# RZ/A1H register map
Vendor: Renesas
Registers are 32-bit, read-write, reset 0x0 unless marked. A register's access mark holds for its fields unless they carry their own. Offsets are from the block's base; [hi:lo] are bit positions; {n}, {i} and the like mark numbered series.

## RSPI0
Base 0xE800C800
Same registers: RSPI1 0xE800D000, RSPI2 0xE800D800, RSPI3 0xE800E000, RSPI4 0xE800E800
0x00 SPCR 8-bit
0x01 SSLP 8-bit
0x02 SPPCR 8-bit
0x03 SPSR 8-bit
0x04 SPDR
0x08 SPSCR 8-bit
0x09 SPSSR 8-bit
0x0A SPBR 8-bit
0x0B SPDCR 8-bit
0x0C SPCKD 8-bit
0x0D SSLND 8-bit
0x0E SPND 8-bit
{0x10+2i} SPCMD{i} 16-bit (i=0..3)
0x20 SPBFCR 8-bit
0x22 SPBFDR 16-bit

## RTC
Base 0xFCFF1000
0x00 R64CNT 8-bit
0x02 RSECCNT 8-bit
0x04 RMINCNT 8-bit
0x06 RHRCNT 8-bit
0x08 RWKCNT 8-bit
0x0A RDAYCNT 8-bit
0x0C RMONCNT 8-bit
0x0E RYRCNT 16-bit
0x10 RSECAR 8-bit
0x12 RMINAR 8-bit
0x14 RHRAR 8-bit
0x16 RWKAR 8-bit
0x18 RDAYAR 8-bit
0x1A RMONAR 8-bit
0x1C RCR1 8-bit
0x1E RCR2 8-bit
0x20 RYRAR 16-bit
0x24 RCR3 8-bit
0x26 RCR5 8-bit
0x2A RFRH 16-bit
0x2C RFRL 16-bit

## SCIF0
Base 0xE8007000
Same registers: SCIF1 0xE8007800, SCIF2 0xE8008000, SCIF3 0xE8008800, SCIF4 0xE8009000, SCIF5 0xE8009800, SCIF6 0xE800A000, SCIF7 0xE800A800
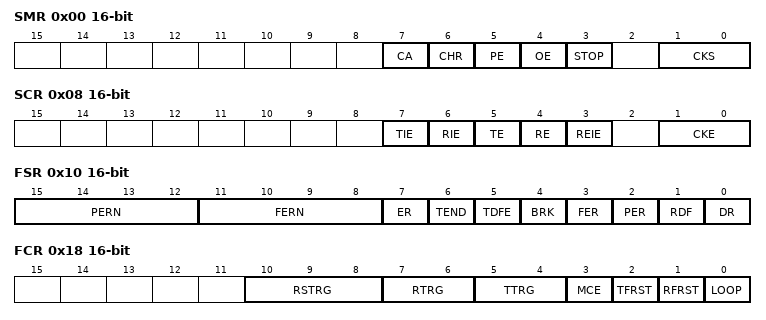
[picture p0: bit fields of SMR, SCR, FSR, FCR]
0x00 SMR 16-bit — SCSMR
  [7] CA
  [6] CHR
  [5] PE
  [4] OE
  [3] STOP
  [1:0] CKS
    0=DIVIDE_BY_1 (P1ϕ); 1=DIVIDE_BY_4 (P1ϕ/4); 2=DIVIDE_BY_16 (P1ϕ/16); 3=DIVIDE_BY_64 (P1ϕ/64)
0x04 BRR 8-bit — SCBRR
  [7:0] D
0x08 SCR 16-bit — SCSCR
  [7] TIE
  [6] RIE
  [5] TE
  [4] RE
  [3] REIE
  [1:0] CKE
    0=INTERNAL_SCK_IN (Asynchronous mode: Internal clock, SCK pin used for input (input signal is ignored). Clock synchronous mode: Internal clock, SCK pin used for synchronous clock output); 1=INTERNAL_SCK_OUT (Internal clock, SCK pin used for synchronous clock output); 2=EXTERNAL_SCK_IN (External clock, SCK pin used for synchronous clock input)
0x0C FTDR 8-bit — SCFTDR
  [7:0] D
0x10 FSR 16-bit — SCFSR
  [15:12] PERN, [11:8] FERN, [7] ER, [6] TEND, [5] TDFE, [4] BRK, [3] FER, [2] PER, [1] RDF, [0] DR
0x14 FRDR 8-bit — SCFRDR
  [7:0] D
0x18 FCR 16-bit — SCFCR
  [10:8] RSTRG
    0=GE_15_BYTES (15 bytes); 1=GE_1_BYTE (1 byte); 2=GE_4_BYTES (4 bytes); 3=GE_6_BYTES (6 bytes); 4=GE_8_BYTES (8 bytes); 5=GE_10_BYTES (10 bytes); 6=GE_12_BYTES (12 bytes); 7=GE_14_BYTES (14 bytes)
  [7:6] RTRG
  [5:4] TTRG
    0=LE_8_BYTES (8 bytes); 1=LE_4_BYTES (4 bytes); 2=LE_2_BYTES (2 bytes); 3=EQ_0_BYTES (0 bytes)
  [3] MCE
  [2] TFRST
  [1] RFRST
  [0] LOOP
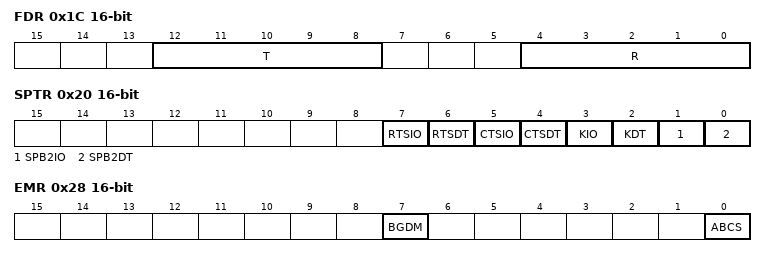
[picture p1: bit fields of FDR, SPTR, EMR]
0x1C FDR 16-bit — SCFDR
  [12:8] T, [4:0] R
0x20 SPTR 16-bit — SCSPTR
  [7] RTSIO, [6] RTSDT, [5] CTSIO, [4] CTSDT, [3] KIO, [2] KDT, [1] SPB2IO, [0] SPB2DT
0x24 LSR 16-bit — SCLSR
  [0] ORER
0x28 EMR 16-bit — SCEMR
  [7] BGDM, [0] ABCS

## SCIM0
Base 0xE800B000
Same registers: SCIM1 0xE800B800
0x00 SMR 8-bit
0x01 BRR 8-bit
0x02 SCR 8-bit
0x03 TDR 8-bit
0x04 SSR 8-bit
0x05 RDR 8-bit
0x06 SCMR 8-bit
0x07 SEMR 8-bit
0x08 SNFR 8-bit
0x0D SECR 8-bit

## SCUX
Base 0xE8208000
{0x0+0x100*i} IPCIR_IPC0_{i} (i=0..3)
{0x4+0x100*i} IPSLR_IPC0_{i} (i=0..3)
{0x400+0x100*i} OPCIR_OPC0_{i} (i=0..3)
{0x404+0x100*i} OPSLR_OPC0_{i} (i=0..3)
{0x800+0x100*i} FFDIR_FFD0_{i} (i=0..3)
{0x804+0x100*i} FDAIR_FFD0_{i} (i=0..3)
{0x808+0x100*i} DRQSR_FFD0_{i} (i=0..3)
{0x80C+0x100*i} FFDPR_FFD0_{i} (i=0..3)
{0x810+0x100*i} FFDBR_FFD0_{i} (i=0..3)
{0x814+0x100*i} DEVMR_FFD0_{i} (i=0..3)
{0x81C+0x100*i} DEVCR_FFD0_{i} (i=0..3)
{0xC00+0x100*i} FFUIR_FFU0_{i} (i=0..3)
{0xC04+0x100*i} FUAIR_FFU0_{i} (i=0..3)
{0xC08+0x100*i} URQSR_FFU0_{i} (i=0..3)
{0xC0C+0x100*i} FFUPR_FFU0_{i} (i=0..3)
{0xC10+0x100*i} UEVMR_FFU0_{i} (i=0..3)
{0xC18+0x100*i} UEVCR_FFU0_{i} (i=0..3)
0x1000 SRCIR0_2SRC0_0
0x1004 SADIR0_2SRC0_0
0x1008 SRCBR0_2SRC0_0
0x100C IFSCR0_2SRC0_0
0x1010 IFSVR0_2SRC0_0
0x1014 SRCCR0_2SRC0_0
0x1018 MNFSR0_2SRC0_0
0x101C BFSSR0_2SRC0_0
0x1020 SC2SR0_2SRC0_0
0x1024 WATSR0_2SRC0_0
0x1028 SEVMR0_2SRC0_0
0x1030 SEVCR0_2SRC0_0
0x1034 SRCIR1_2SRC0_0
0x1038 SADIR1_2SRC0_0
0x103C SRCBR1_2SRC0_0
0x1040 IFSCR1_2SRC0_0
0x1044 IFSVR1_2SRC0_0
0x1048 SRCCR1_2SRC0_0
0x104C MNFSR1_2SRC0_0
0x1050 BFSSR1_2SRC0_0
0x1054 SC2SR1_2SRC0_0
0x1058 WATSR1_2SRC0_0
0x105C SEVMR1_2SRC0_0
0x1064 SEVCR1_2SRC0_0
0x1068 SRCIRR_2SRC0_0
0x1100 SRCIR0_2SRC0_1
0x1104 SADIR0_2SRC0_1
0x1108 SRCBR0_2SRC0_1
0x110C IFSCR0_2SRC0_1
0x1110 IFSVR0_2SRC0_1
0x1114 SRCCR0_2SRC0_1
0x1118 MNFSR0_2SRC0_1
0x111C BFSSR0_2SRC0_1
0x1120 SC2SR0_2SRC0_1
0x1124 WATSR0_2SRC0_1
0x1128 SEVMR0_2SRC0_1
0x1130 SEVCR0_2SRC0_1
0x1134 SRCIR1_2SRC0_1
0x1138 SADIR1_2SRC0_1
0x113C SRCBR1_2SRC0_1
0x1140 IFSCR1_2SRC0_1
0x1144 IFSVR1_2SRC0_1
0x1148 SRCCR1_2SRC0_1
0x114C MNFSR1_2SRC0_1
0x1150 BFSSR1_2SRC0_1
0x1154 SC2SR1_2SRC0_1
0x1158 WATSR1_2SRC0_1
0x115C SEVMR1_2SRC0_1
0x1164 SEVCR1_2SRC0_1
0x1168 SRCIRR_2SRC0_1
{0x1200+0x100*i} DVUIR_DVU0_{i} (i=0..3)
{0x1204+0x100*i} VADIR_DVU0_{i} (i=0..3)
{0x1208+0x100*i} DVUBR_DVU0_{i} (i=0..3)
{0x120C+0x100*i} DVUCR_DVU0_{i} (i=0..3)
{0x1210+0x100*i} ZCMCR_DVU0_{i} (i=0..3)
{0x1214+0x100*i} VRCTR_DVU0_{i} (i=0..3)
{0x1218+0x100*i} VRPDR_DVU0_{i} (i=0..3)
{0x121C+0x100*i} VRDBR_DVU0_{i} (i=0..3)
{0x1220+0x100*i} VRWTR_DVU0_{i} (i=0..3)
{0x1224+4i} VOL{i}R_DVU0_0 (i=0..7)
{0x1244+0x100*i} DVUER_DVU0_{i} (i=0..3)
{0x1248+0x100*i} DVUSR_DVU0_{i} (i=0..3)
{0x124C+0x100*i} VEVMR_DVU0_{i} (i=0..3)
{0x1254+0x100*i} VEVCR_DVU0_{i} (i=0..3)
{0x1324+4i} VOL{i}R_DVU0_1 (i=0..7)
{0x1424+4i} VOL{i}R_DVU0_2 (i=0..7)
{0x1524+4i} VOL{i}R_DVU0_3 (i=0..7)
0x1600 MIXIR_MIX0_0
0x1604 MADIR_MIX0_0
0x1608 MIXBR_MIX0_0
0x160C MIXMR_MIX0_0
0x1610 MVPDR_MIX0_0
0x1614 MDBAR_MIX0_0
0x1618 MDBBR_MIX0_0
0x161C MDBCR_MIX0_0
0x1620 MDBDR_MIX0_0
0x1624 MDBER_MIX0_0
0x1628 MIXSR_MIX0_0
0x1700 SWRSR_CIM
0x1704 DMACR_CIM
{0x1708+4i} DMATD{i}_CIM (i=0..3)
{0x1718+4i} DMATU{i}_CIM (i=0..3)
0x1738 SSIRSEL_CIM
{0x173C+4i} FDTSEL{i}_CIM (i=0..3)
{0x174C+4i} FUTSEL{i}_CIM (i=0..3)
0x175C SSIPMD_CIM
0x1760 SSICTRL_CIM
{0x1764+4i} SRCRSEL{i}_CIM (i=0..3)
0x1774 MIXRSEL_CIM

## SDG0
Base 0xFCFF4800
Same registers: SDG1 0xFCFF4A00, SDG2 0xFCFF4C00, SDG3 0xFCFF4E00
0x00 SGCR1 8-bit
0x01 SGCSR 8-bit
0x02 SGCR2 8-bit
0x03 SGLR 8-bit
0x04 SGTFR 8-bit
0x05 SGSFR 8-bit

## SPDIF
Base 0xE8012000
0x00 TLCA
0x04 TRCA
0x08 TLCS
0x0C TRCS
0x10 TUI
0x14 RLCA
0x18 RRCA
0x1C RLCS
0x20 RRCS
0x24 RUI
0x28 CTRL
0x2C STAT
0x30 TDAD
0x34 RDAD

## SPIBSC0
Base 0x3FEFA000
Same registers: SPIBSC1 0x3FEFB000
0x00 CMNCR
0x04 SSLDR
0x08 SPBCR
0x0C DRCR
0x10 DRCMR
0x14 DREAR
0x18 DROPR
0x1C DRENR
0x20 SMCR
0x24 SMCMR
0x28 SMADR
0x2C SMOPR
0x30 SMENR
0x38 SMRDR0
0x3C SMRDR1
0x40 SMWDR0
0x44 SMWDR1
0x48 CMNSR
0x50 CKDLY
0x58 DRDMCR
0x5C DRDRENR
0x60 SMDMCR
0x64 SMDRENR
0x68 SPODLY

## SSIF0
Base 0xE820B000
Same registers: SSIF1 0xE820B800, SSIF2 0xE820C000, SSIF3 0xE820C800, SSIF4 0xE820D000, SSIF5 0xE820D800
0x00 SSICR
0x04 SSISR
0x10 SSIFCR
0x14 SSIFSR
0x18 SSIFTDR
0x1C SSIFRDR
0x20 SSITDMR
0x24 SSIFCCR
0x28 SSIFCMR
0x2C SSIFCSR

## USB200
Base 0xE8010000
Same registers: USB201 0xE8207000
0x00 SYSCFG0 16-bit
0x02 BUSWAIT 16-bit
0x04 SYSSTS0 16-bit
0x08 DVSTCTR0 16-bit
0x0C TESTMODE 16-bit
0x10 D0FBCFG 16-bit
0x12 D1FBCFG 16-bit
0x14 CFIFO
0x18 D0FIFO
0x1C D1FIFO
0x20 CFIFOSEL 16-bit
0x22 CFIFOCTR 16-bit
0x28 D0FIFOSEL 16-bit
0x2A D0FIFOCTR 16-bit
0x2C D1FIFOSEL 16-bit
0x2E D1FIFOCTR 16-bit
0x30 INTENB0 16-bit
0x32 INTENB1 16-bit
0x36 BRDYENB 16-bit
0x38 NRDYENB 16-bit
0x3A BEMPENB 16-bit
0x3C SOFCFG 16-bit
0x40 INTSTS0 16-bit
0x42 INTSTS1 16-bit
0x46 BRDYSTS 16-bit
0x48 NRDYSTS 16-bit
0x4A BEMPSTS 16-bit
0x4C FRMNUM 16-bit
0x4E UFRMNUM 16-bit
0x50 USBADDR 16-bit
0x54 USBREQ 16-bit
0x56 USBVAL 16-bit
0x58 USBINDX 16-bit
0x5A USBLENG 16-bit
0x5C DCPCFG 16-bit
0x5E DCPMAXP 16-bit
0x60 DCPCTR 16-bit
0x64 PIPESEL 16-bit
0x68 PIPECFG 16-bit
0x6A PIPEBUF 16-bit
0x6C PIPEMAXP 16-bit
0x6E PIPEPERI 16-bit
{0x6E+2i} PIPE{i}CTR 16-bit (i=1..9)
0x82 PIPEACTR 16-bit
0x84 PIPEBCTR 16-bit
0x86 PIPECCTR 16-bit
0x88 PIPEDCTR 16-bit
0x8A PIPEECTR 16-bit
0x8C PIPEFCTR 16-bit
{0x8C+4i} PIPE{i}TRE 16-bit (i=1..5)
{0x8E+4i} PIPE{i}TRN 16-bit (i=1..5)
0xA4 PIPEBTRE 16-bit
0xA6 PIPEBTRN 16-bit
0xA8 PIPECTRE 16-bit
0xAA PIPECTRN 16-bit
0xAC PIPEDTRE 16-bit
0xAE PIPEDTRN 16-bit
0xB0 PIPEETRE 16-bit
0xB2 PIPEETRN 16-bit
0xB4 PIPEFTRE 16-bit
0xB6 PIPEFTRN 16-bit
0xB8 PIPE9TRE 16-bit
0xBA PIPE9TRN 16-bit
0xBC PIPEATRE 16-bit
0xBE PIPEATRN 16-bit
{0xD0+2i} DEVADD{i} 16-bit (i=0..9)
0xE4 DEVADDA 16-bit
0x102 SUSPMODE 16-bit
{0x160+4i} D0FIFOB{i} (i=0..7)
{0x180+4i} D1FIFOB{i} (i=0..7)

## WDT
Base 0xFCFE0000
0x00 WTCSR 16-bit
0x02 WTCNT 16-bit
0x04 WRCSR 16-bit
